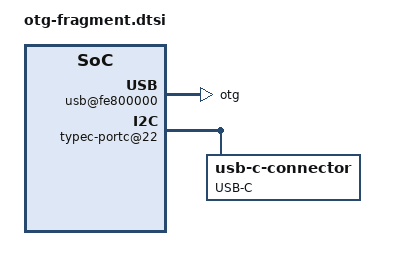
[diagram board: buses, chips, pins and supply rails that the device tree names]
/*
 * One-KVM OTG configuration for the NanoPC-T4 USB-C port.
 *
 * The port is the dwc3_0 controller.  Keep dr_mode="otg": setting
 * "peripheral" makes the RK3399 PHY force its GRF IDDIG override, which
 * breaks the D+ pull-up and leaves the host unable to enumerate the gadget.
 * Instead default the dwc3 role switch to peripheral and describe the
 * FUSB302 Type-C port as a sink-only device; TCPM then presents Rd on CC
 * and drives the role switch.
 *
 * This must expose a UDC for One-KVM's:
 *   - HID: virtual keyboard and mouse
 *   - mass storage: virtual CD-ROM / disk
 *   - UVC: video capture
 *
 * The node paths come from the pinned Armbian base image and are resolved
 * with &{/path} references, so no DTS labels are required.
 */
&{/usb@fe800000/usb@fe800000} {
	dr_mode = "otg";
	usb-role-switch;
	role-switch-default-mode = "peripheral";
	maximum-speed = "high-speed";
};

&{/i2c@ff3d0000/typec-portc@22} {
	connector {
		compatible = "usb-c-connector";
		label = "USB-C";
		type = "receptacle";
		data-role = "device";
		power-role = "sink";
		try-power-role = "sink";
		op-sink-microwatt = <1000000>;
		pd-disable;
		typec-power-opmode = "default";
		usb-role-switch = <&{/usb@fe800000/usb@fe800000}>;
	};
};
